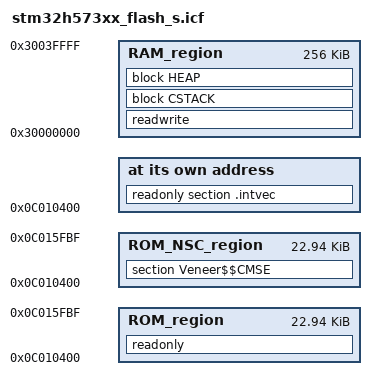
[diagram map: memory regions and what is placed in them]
/*###ICF### Section handled by ICF editor, don't touch! ****/
/*-Editor annotation file-*/
/* IcfEditorFile="$TOOLKIT_DIR$\config\ide\IcfEditor\cortex_v1_0.xml" */
/*-Specials-*/
define exported symbol S_CODE_OFFSET =0x10000; /* This define is updated automatically from ROT_BOOT project */
define exported symbol S_CODE_SIZE = 0x6000; /* This define is updated automatically from ROT_BOOT project */
define exported symbol NS_CODE_OFFSET = S_CODE_OFFSET + S_CODE_SIZE; /* Non secure code Offset */
define exported symbol IMAGE_HEADER_SIZE = 0x400; /* mcuboot headre size */
define symbol TRAILER_MAX_SIZE = 0x40; /* max size trailer */

define exported symbol __ICFEDIT_intvec_start__ = 0x0C000000 + S_CODE_OFFSET + IMAGE_HEADER_SIZE;
/*-Memory Regions-*/
define exported symbol __ICFEDIT_region_ROM_start__     = 0x0C000000 + S_CODE_OFFSET + IMAGE_HEADER_SIZE;
define symbol __ICFEDIT_region_ROM_end__       = 0x0C000000 + NS_CODE_OFFSET - TRAILER_MAX_SIZE - 1;
define symbol __ICFEDIT_region_ROM_NSC_start__ = __ICFEDIT_region_ROM_start__;
define symbol __ICFEDIT_region_ROM_NSC_end__   = __ICFEDIT_region_ROM_end__;
define symbol __ICFEDIT_region_RAM_start__     = 0x30000000;
define symbol __ICFEDIT_region_RAM_end__       = 0x3003FFFF;

/*-Sizes-*/
define symbol __ICFEDIT_size_cstack__ = 0x400;
define symbol __ICFEDIT_size_heap__   = 0x200;
/**** End of ICF editor section. ###ICF###*/

define symbol __region_ROM_NS_start__    = 0x08100000;
define symbol __region_ROM_NS_end__      = 0x081FFFFF;

define memory mem with size = 4G;
define region ROM_region      = mem:[from __ICFEDIT_region_ROM_start__     to __ICFEDIT_region_ROM_end__];
define region ROM_NSC_region  = mem:[from __ICFEDIT_region_ROM_NSC_start__ to __ICFEDIT_region_ROM_NSC_end__];
define region RAM_region      = mem:[from __ICFEDIT_region_RAM_start__     to __ICFEDIT_region_RAM_end__];

define exported symbol __VTOR_TABLE_start       = __ICFEDIT_intvec_start__;
define exported symbol __VTOR_TABLE_NS_start    = __region_ROM_NS_start__;

define block CSTACK    with alignment = 8, size = __ICFEDIT_size_cstack__   { };
define block HEAP      with alignment = 8, size = __ICFEDIT_size_heap__     { };

initialize by copy { readwrite };
do not initialize  { section .noinit };

place at address mem:__ICFEDIT_intvec_start__ { readonly section .intvec };

place in ROM_region     { readonly };
place in ROM_NSC_region { section Veneer$$CMSE };
place in RAM_region     { readwrite,
                          block CSTACK, block HEAP };
